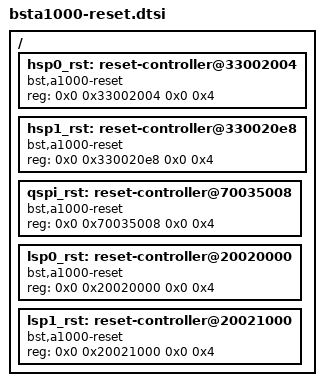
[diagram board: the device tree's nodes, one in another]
// SPDX-License-Identifier: GPL-2.0
#include <dt-bindings/reset/bsta1000-reset.h>

/ {
	hsp0_rst: reset-controller@33002004 {
			compatible = "bst,a1000-reset";
			reg = <0x0 0x33002004 0x0 0x4>;
			#reset-cells = <1>;
			u-boot,dm-spl;
		};

	hsp1_rst: reset-controller@330020e8 {
			compatible = "bst,a1000-reset";
			reg = <0x0 0x330020e8 0x0 0x4>;
			#reset-cells = <1>;
			u-boot,dm-spl;
		};

	qspi_rst: reset-controller@70035008 {
			compatible = "bst,a1000-reset";
			reg = <0x0 0x70035008 0x0 0x4>;
			#reset-cells = <1>;
			u-boot,dm-spl;
		};

	lsp0_rst: reset-controller@20020000 {
			compatible = "bst,a1000-reset";
			reg = <0x0 0x20020000 0x0 0x4>;
			#reset-cells = <1>;
			u-boot,dm-spl;
		};

	lsp1_rst: reset-controller@20021000 {
			compatible = "bst,a1000-reset";
			reg = <0x0 0x20021000 0x0 0x4>;
			#reset-cells = <1>;
			u-boot,dm-spl;
		};
};
